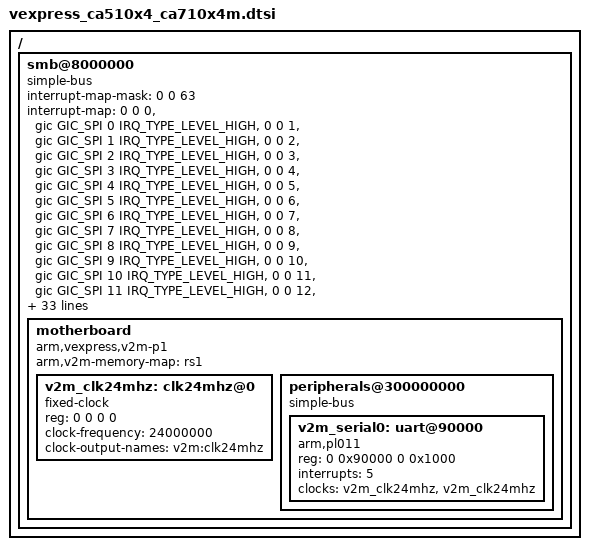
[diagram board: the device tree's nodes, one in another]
/*
 * SPDX-License-Identifier: Apache-2.0
 * Copyright (c) 2019 KapaXL (kapa.xl@outlook.com)
 *
 * FVP Motherboard component
 */

#define GIC_SPI 0
#define GIC_PPI 1

#define IRQ_TYPE_NONE		0
#define IRQ_TYPE_EDGE_RISING	1
#define IRQ_TYPE_EDGE_FALLING	2
#define IRQ_TYPE_EDGE_BOTH	(IRQ_TYPE_EDGE_FALLING | IRQ_TYPE_EDGE_RISING)
#define IRQ_TYPE_LEVEL_HIGH	4
#define IRQ_TYPE_LEVEL_LOW	8

#define GIC_CPU_MASK_RAW(x) ((x) << 8)
#define GIC_CPU_MASK_SIMPLE(num) GIC_CPU_MASK_RAW((1 << (num)) - 1)

/ {
	smb@8000000 {
		compatible = "simple-bus";
		#address-cells = <2>;
		#size-cells = <2>;

		ranges = <0 0 0 0x08000000 0 0x04000000>,
			 <1 0 0 0x14000000 0 0x04000000>,
			 <2 0 0 0x18000000 0 0x04000000>,
			 <3 0 0 0x1c000000 0 0x04000000>,
			 <4 0 0 0x0c000000 0 0x04000000>,
			 <5 0 0 0x10000000 0 0x04000000>;

		#interrupt-cells = <1>;
		interrupt-map-mask = <0 0 63>;
		interrupt-map = <0 0  0 &gic GIC_SPI  0 IRQ_TYPE_LEVEL_HIGH>,
				<0 0  1 &gic GIC_SPI  1 IRQ_TYPE_LEVEL_HIGH>,
				<0 0  2 &gic GIC_SPI  2 IRQ_TYPE_LEVEL_HIGH>,
				<0 0  3 &gic GIC_SPI  3 IRQ_TYPE_LEVEL_HIGH>,
				<0 0  4 &gic GIC_SPI  4 IRQ_TYPE_LEVEL_HIGH>,
				<0 0  5 &gic GIC_SPI  5 IRQ_TYPE_LEVEL_HIGH>,
				<0 0  6 &gic GIC_SPI  6 IRQ_TYPE_LEVEL_HIGH>,
				<0 0  7 &gic GIC_SPI  7 IRQ_TYPE_LEVEL_HIGH>,
				<0 0  8 &gic GIC_SPI  8 IRQ_TYPE_LEVEL_HIGH>,
				<0 0  9 &gic GIC_SPI  9 IRQ_TYPE_LEVEL_HIGH>,
				<0 0 10 &gic GIC_SPI 10 IRQ_TYPE_LEVEL_HIGH>,
				<0 0 11 &gic GIC_SPI 11 IRQ_TYPE_LEVEL_HIGH>,
				<0 0 12 &gic GIC_SPI 12 IRQ_TYPE_LEVEL_HIGH>,
				<0 0 13 &gic GIC_SPI 13 IRQ_TYPE_LEVEL_HIGH>,
				<0 0 14 &gic GIC_SPI 14 IRQ_TYPE_LEVEL_HIGH>,
				<0 0 15 &gic GIC_SPI 15 IRQ_TYPE_LEVEL_HIGH>,
				<0 0 16 &gic GIC_SPI 16 IRQ_TYPE_LEVEL_HIGH>,
				<0 0 17 &gic GIC_SPI 17 IRQ_TYPE_LEVEL_HIGH>,
				<0 0 18 &gic GIC_SPI 18 IRQ_TYPE_LEVEL_HIGH>,
				<0 0 19 &gic GIC_SPI 19 IRQ_TYPE_LEVEL_HIGH>,
				<0 0 20 &gic GIC_SPI 20 IRQ_TYPE_LEVEL_HIGH>,
				<0 0 21 &gic GIC_SPI 21 IRQ_TYPE_LEVEL_HIGH>,
				<0 0 22 &gic GIC_SPI 22 IRQ_TYPE_LEVEL_HIGH>,
				<0 0 23 &gic GIC_SPI 23 IRQ_TYPE_LEVEL_HIGH>,
				<0 0 24 &gic GIC_SPI 24 IRQ_TYPE_LEVEL_HIGH>,
				<0 0 25 &gic GIC_SPI 25 IRQ_TYPE_LEVEL_HIGH>,
				<0 0 26 &gic GIC_SPI 26 IRQ_TYPE_LEVEL_HIGH>,
				<0 0 27 &gic GIC_SPI 27 IRQ_TYPE_LEVEL_HIGH>,
				<0 0 28 &gic GIC_SPI 28 IRQ_TYPE_LEVEL_HIGH>,
				<0 0 29 &gic GIC_SPI 29 IRQ_TYPE_LEVEL_HIGH>,
				<0 0 30 &gic GIC_SPI 30 IRQ_TYPE_LEVEL_HIGH>,
				<0 0 31 &gic GIC_SPI 31 IRQ_TYPE_LEVEL_HIGH>,
				<0 0 32 &gic GIC_SPI 32 IRQ_TYPE_LEVEL_HIGH>,
				<0 0 33 &gic GIC_SPI 33 IRQ_TYPE_LEVEL_HIGH>,
				<0 0 34 &gic GIC_SPI 34 IRQ_TYPE_LEVEL_HIGH>,
				<0 0 35 &gic GIC_SPI 35 IRQ_TYPE_LEVEL_HIGH>,
				<0 0 36 &gic GIC_SPI 36 IRQ_TYPE_LEVEL_HIGH>,
				<0 0 37 &gic GIC_SPI 37 IRQ_TYPE_LEVEL_HIGH>,
				<0 0 38 &gic GIC_SPI 38 IRQ_TYPE_LEVEL_HIGH>,
				<0 0 39 &gic GIC_SPI 39 IRQ_TYPE_LEVEL_HIGH>,
				<0 0 40 &gic GIC_SPI 40 IRQ_TYPE_LEVEL_HIGH>,
				<0 0 41 &gic GIC_SPI 41 IRQ_TYPE_LEVEL_HIGH>,
				<0 0 42 &gic GIC_SPI 42 IRQ_TYPE_LEVEL_HIGH>,
				<0 0 43 &gic GIC_SPI 43 IRQ_TYPE_LEVEL_HIGH>,
				<0 0 44 &gic GIC_SPI 44 IRQ_TYPE_LEVEL_HIGH>;

		motherboard {
			arm,v2m-memory-map = "rs1";
			compatible = "arm,vexpress,v2m-p1", "simple-bus";
			#address-cells = <2>;
			#size-cells = <2>;
			ranges;

			v2m_clk24mhz: clk24mhz@0 {
				compatible = "fixed-clock";
				#clock-cells = <0>;
				reg = <0 0 0 0>;
				clock-frequency = <24000000>;
				clock-output-names = "v2m:clk24mhz";
			};

			peripherals@300000000 {
				compatible = "simple-bus";
				#address-cells = <2>;
				#size-cells = <2>;
				ranges = <0 0 3 0 0 0x200000>;

				v2m_serial0: uart@90000 {
					compatible = "arm,pl011", "arm,primecell";
					reg = <0 0x90000 0 0x1000>;
					interrupts = <5>;
					clocks = <&v2m_clk24mhz>, <&v2m_clk24mhz>;
					clock-names = "uartclk", "apb_pclk";
				};
			};
		};
	};
};
